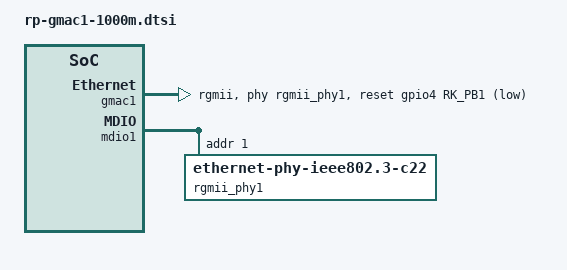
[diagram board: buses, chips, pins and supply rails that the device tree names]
&gmac1 {
    phy-mode = "rgmii";
    clock_in_out = "output";

    snps,reset-gpio = <&gpio4 RK_PB1 GPIO_ACTIVE_LOW>; //
    snps,reset-active-low;
    /* Reset time is 20ms, 100ms for rtl8211f */
    snps,reset-delays-us = <0 20000 100000>;

    pinctrl-names = "default";
    pinctrl-0 = <&eth1m0_miim
             &eth1m0_tx_bus2
             &eth1m0_rx_bus2
             &eth1m0_rgmii_clk
             &eth1m0_rgmii_bus
             &ethm0_clk1_25m_out>;

    tx_delay = <0x19>;
    rx_delay = <0x22>;

    phy-handle = <&rgmii_phy1>;
    status = "okay";
};

&mdio1 {
    rgmii_phy1: phy@1 {
        compatible = "ethernet-phy-ieee802.3-c22";
        reg = <0x1>;
        clocks = <&cru REFCLKO25M_GMAC1_OUT>;
    };
};
